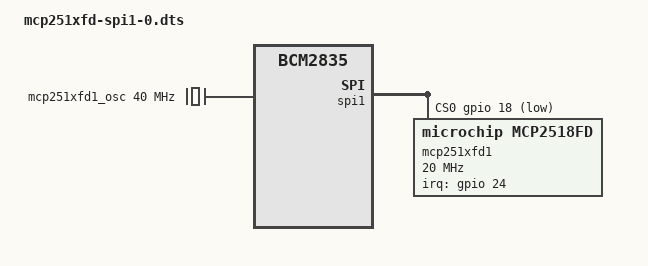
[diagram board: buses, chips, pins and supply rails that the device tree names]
// Device tree overlay for MCP2518FD CAN controller on SPI1.0
/dts-v1/;
/plugin/;

/ {
    compatible = "brcm,bcm2835";

    fragment@0 {
        target = <&spi1>;
        __overlay__ {
            status = "okay";
            #address-cells = <1>;
            #size-cells = <0>;
            cs-gpios = <&gpio 18 1>; /* GPIO18, active low */

            mcp251xfd1: mcp251xfd@0 {
                compatible = "microchip,mcp2518fd";
                reg = <0>;
                spi-max-frequency = <20000000>;
                interrupt-parent = <&gpio>;
                interrupts = <24 8>; /* IRQ_TYPE_LEVEL_LOW */
                clocks = <&mcp251xfd1_osc>;
            };
        };
    };

    fragment@1 {
        target-path = "/";
        __overlay__ {
            mcp251xfd1_osc: mcp251xfd1-osc {
                compatible = "fixed-clock";
                #clock-cells = <0>;
                clock-frequency = <40000000>;
            };
        };
    };
};
